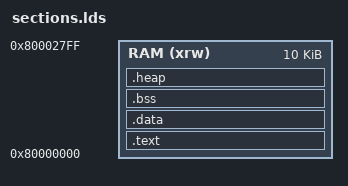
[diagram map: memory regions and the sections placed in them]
MEMORY
{
    RAM (xrw)       : ORIGIN = 0x80000000, LENGTH = 10k /* 1 KB */
}
ENTRY(_start)
SECTIONS {
    /* The program code and other data now goes into RAM */
    .text :
    {
        . = ALIGN(4);
        *(.text)           /* .text sections (code) */
        *(.text*)          /* .text* sections (code) */
        *(.rodata)         /* .rodata sections (constants, strings, etc.) */
        *(.rodata*)        /* .rodata* sections (constants, strings, etc.) */
        *(.srodata)        /* .rodata sections (constants, strings, etc.) */
        *(.srodata*)       /* .rodata* sections (constants, strings, etc.) */
        . = ALIGN(4);
        _etext = .;        /* define a global symbol at end of code */
        _sidata = _etext;  /* This is used by the startup in order to initialize the .data secion */
    } >RAM

    /* Initialized data section */
    .data :
    {
        . = ALIGN(4);
        _sdata = .;        /* create a global symbol at data start */
        _ram_start = .;    /* create a global symbol at ram start for garbage collector */
        . = ALIGN(4);
        *(.data)           /* .data sections */
        *(.data*)          /* .data* sections */
        *(.sdata)          /* .sdata sections */
        *(.sdata*)         /* .sdata* sections */
        . = ALIGN(4);
        _edata = .;        /* define a global symbol at data end */
    } >RAM

    /* Uninitialized data section */
    .bss :
    {
        . = ALIGN(4);
        _sbss = .;         /* define a global symbol at bss start */
        *(.bss)
        *(.bss*)
        *(.sbss)
        *(.sbss*)
        *(COMMON)

        . = ALIGN(4);
        _ebss = .;         /* define a global symbol at bss end */
    } >RAM

    /* Heap section */
    .heap :
    {
        . = ALIGN(4);
        _heap_start = .;    /* define a global symbol at heap start */
    } >RAM
}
